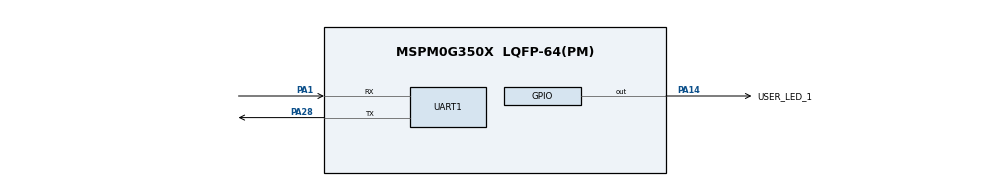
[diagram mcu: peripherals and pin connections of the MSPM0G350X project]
/**
 * @cliArgs --device "MSPM0G350X" --package "LQFP-64(PM)" --part "Default" --product "mspm0_sdk@1.30.00.03"
 * @versions {"tool":"1.19.0+3426"}
 */

/**
 * Import the modules used in this configuration.
 */
const GPIO   = scripting.addModule("/ti/driverlib/GPIO", {}, false);
const GPIO1  = GPIO.addInstance();
const SYSCTL = scripting.addModule("/ti/driverlib/SYSCTL");
const UART   = scripting.addModule("/ti/driverlib/UART", {}, false);
const UART1  = UART.addInstance();

/**
 * Write custom configuration values to the imported modules.
 */
GPIO1.$name                         = "GPIO_LEDS";
GPIO1.port                          = "PORTA";
GPIO1.associatedPins.create(4);
GPIO1.associatedPins[0].$name       = "USER_LED_1";
GPIO1.associatedPins[0].assignedPin = "14";
GPIO1.associatedPins[0].pin.$assign = "PA14";
GPIO1.associatedPins[1].$name       = "USER_LED_2";
GPIO1.associatedPins[1].assignedPin = "26";
GPIO1.associatedPins[2].$name       = "USER_LED_3";
GPIO1.associatedPins[2].assignedPin = "27";
GPIO1.associatedPins[3].$name       = "USER_TEST";

const Board = scripting.addModule("/ti/driverlib/Board", {}, false);

SYSCTL.forceDefaultClkConfig = true;
SYSCTL.clockTreeEn           = true;

UART1.$name                    = "UART_0";
UART1.targetBaudRate           = 115200;
UART1.enabledInterrupts        = ["RX"];
UART1.peripheral.$assign       = "UART0";
UART1.peripheral.rxPin.$assign = "PA1";
UART1.peripheral.txPin.$assign = "PA28";
UART1.txPinConfig.$name        = "ti_driverlib_gpio_GPIOPinGeneric0";
UART1.rxPinConfig.$name        = "ti_driverlib_gpio_GPIOPinGeneric1";

/**
 * Pinmux solution for unlocked pins/peripherals. This ensures that minor changes to the automatic solver in a future
 * version of the tool will not impact the pinmux you originally saw.  These lines can be completely deleted in order to
 * re-solve from scratch.
 */
GPIO1.associatedPins[1].pin.$suggestSolution = "PA26";
GPIO1.associatedPins[2].pin.$suggestSolution = "PA27";
GPIO1.associatedPins[3].pin.$suggestSolution = "PA12";
Board.peripheral.$suggestSolution            = "DEBUGSS";
Board.peripheral.swclkPin.$suggestSolution   = "PA20";
Board.peripheral.swdioPin.$suggestSolution   = "PA19";
